// A comment.

VERSION "2.0" // Another comment.

NS_ :

BS_:

BU_: FOO BAR FIE FUM
VAL_TABLE_ State 1 "Enabled" 0 "Disabled" ;

BO_ 2147558192 Foo: 8 FOO
 SG_ Foo : 0|12@0- (0.01,250) [229.53|270.47] "degK"  BAR
 SG_ Bar : 24|32@0- (0.1,0) [0|5] "m"  FOO

BO_ 2147558193 Fum: 5 FOO
 SG_ Fum : 0|12@1- (1,0) [0|10] ""  BAR
 SG_ Fam : 12|12@1- (1,0) [0|8] ""  BAR

BO_ 2147558194 Bar: 4 FOO
 SG_ Binary32 : 0|32@1- (1,0) [0|0] ""  FUM

BO_ 2147558195 CanFd: 64 FOO
 SG_ Fie : 0|64@1+ (1,0) [0|0] ""  FUM
 SG_ Fas : 64|64@1+ (1,0) [0|0] "" Vector__XXX

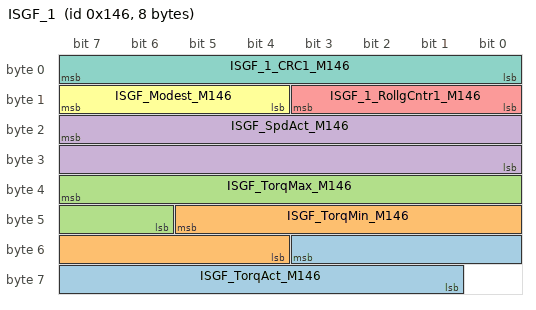
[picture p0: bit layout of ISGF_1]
BO_ 326 ISGF_1: 8 PDC01
 SG_ ISGF_TorqAct_M146 : 51|11@0+ (0.25,-255) [-255|255] "Nm" Vector__XXX
 SG_ ISGF_TorqMin_M146 : 45|10@0+ (0.25,-255) [-255|0] "Nm" Vector__XXX
 SG_ ISGF_TorqMax_M146 : 39|10@0+ (0.25,0) [0|255] "Nm" Vector__XXX
 SG_ ISGF_SpdAct_M146 : 23|16@0+ (1,-32767) [-32766|32767] "rpm" Vector__XXX
 SG_ ISGF_1_RollgCntr1_M146 : 11|4@0+ (1,0) [0|14] "" Vector__XXX
 SG_ ISGF_Modest_M146 : 15|4@0+ (1,0) [0|15] "" Vector__XXX
 SG_ ISGF_1_CRC1_M146 : 7|8@0+ (1,0) [0|255] "" Vector__XXX

BO_ 780 FOOBAR: 8 FIE
 SG_ ACC_02_CRC : 0|12@1- (1,0) [0|1] ""  BAR

CM_ "global comment/全局注释"
CM_ BU_ BAR "fam \"1\"";
CM_ BU_ BAR "dsdsd - qweqweqw";
CM_ BO_ 2147558192 "Foo.";
CM_ SG_ 2147558192 Bar "Bar.";
BA_DEF_  "DBName" STRING ;
BA_DEF_  "Baudrate" INT 0 1000000;
BA_DEF_  "AFloat" FLOAT 0 100;
BA_DEF_  "BusType" STRING ;
BA_DEF_ BU_  "FOO" INT 0 100;
BA_DEF_ BU_  "BAR" STRING ;
BA_DEF_ BO_  "VFrameFormat" ENUM  "StandardCAN","ExtendedCAN","reserved","reserved","reserved","reserved","reserved","reserved","reserved","reserved","reserved","reserved","reserved","reserved","StandardCAN_FD","ExtendedCAN_FD";
BA_DEF_ BO_  "GenMsgCycleTime" INT 0 1000;
BA_DEF_DEF_  "DBName" "";
BA_DEF_DEF_  "Baudrate" 125000;
BA_DEF_DEF_  "AFloat" 0;
BA_DEF_DEF_  "BusType" "";
BA_DEF_DEF_  "FOO" 0;
BA_DEF_DEF_  "BAR" "";
BA_DEF_DEF_  "VFrameFormat" "ExtendedCAN_FD";
BA_DEF_DEF_  "GenMsgCycleTime" 100;
BA_ "DBName" "TheBusName";
BA_ "AFloat" 33.5;
BA_ "BusType" "CAN FD";
BA_ "BAR" BU_ FIE "FUM";
BA_ "FOO" BU_ FIE 1;
BA_ "VFrameFormat" BO_ 2147558192 1;
BA_ "VFrameFormat" BO_ 2147558193 1;
BA_ "GenMsgCycleTime" BO_ 2147558193 1;
BA_ "VFrameFormat" BO_ 2147558194 1;
BA_ "VFrameFormat" BO_ 780 0;
VAL_ 2147558193 Fam 1 "Enabled" 0 "Disabled" ;
VAL_ 326 ISGF_TorqAct_M146 2047 "Invalid" ;
VAL_ 326 ISGF_TorqMin_M146 1023 "Invalid" ;
VAL_ 326 ISGF_TorqMax_M146 1023 "Invalid" ;
VAL_ 326 ISGF_SpdAct_M146 65535 "Invalid" ;

SIG_VALTYPE_ 2147558192 Bar : 1;
SIG_VALTYPE_ 2147558194 Binary32 : 1;
